VERSION ""

NS_ :

BS_:

BU_: XXX
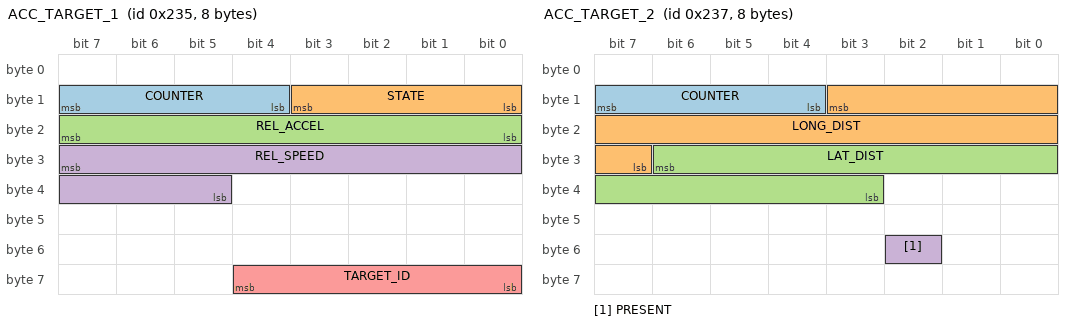
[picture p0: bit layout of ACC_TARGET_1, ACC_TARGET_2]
BO_ 565 ACC_TARGET_1: 8 XXX
 SG_ COUNTER : 15|4@0+ (1,0) [0|15] "" XXX
 SG_ STATE : 11|4@0+ (1,0) [0|15] "" XXX
 SG_ REL_ACCEL : 23|8@0+ (0.125,-12.5) [-12.5|19.375] "m/s^2" XXX
 SG_ REL_SPEED : 31|11@0+ (0.125,-128) [-128|127.875] "m/s" XXX
 SG_ TARGET_ID : 60|5@0+ (1,0) [0|31] "" XXX

BO_ 567 ACC_TARGET_2: 8 XXX
 SG_ COUNTER : 15|4@0+ (1,0) [0|15] "" XXX
 SG_ LONG_DIST : 11|13@0+ (0.025,0) [0|204.775] "m" XXX
 SG_ LAT_DIST : 30|12@0+ (0.01,-20) [-20|20.95] "m" XXX
 SG_ PRESENT : 50|1@0+ (1,0) [0|1] "" XXX

BO_ 569 ACC_TARGET_3: 8 XXX
 SG_ TIMESTAMP : 26|32@0+ (1,0) [0|4294967295] "us" XXX

CM_ "Continental ARS510 front radar (Toyota RAV4 2022-25, fwdRadar 8821F0R03100), radar bus: the target the radar's own ACC follows. The 0x80 object list and 0x85 metadata record span many frames and are decoded by ars510-radar (ars510/).";
CM_ BO_ 565 "ACC target, part 1: 50 Hz, content updated once per 60 ms radar cycle.";
CM_ SG_ 565 STATE "5 = target present, 1 = idle (all other fields zero).";
CM_ SG_ 565 REL_ACCEL "Target acceleration relative to ego.";
CM_ SG_ 565 REL_SPEED "Closing speed relative to ego, negative = closing.";
CM_ SG_ 565 TARGET_ID "Changes when the radar switches to a different target.";
CM_ BO_ 567 "ACC target, part 2: 50 Hz.";
CM_ SG_ 567 LONG_DIST "Distance from the radar.";
CM_ SG_ 567 LAT_DIST "Lateral position, left positive.";
CM_ SG_ 567 PRESENT "1 = target present.";
CM_ BO_ 569 "ACC target, part 3: 50 Hz.";
CM_ SG_ 569 TIMESTAMP "Radar cycle clock: changes once per 60 ms radar cycle, when the ACC target is recomputed.";
VAL_ 565 STATE 5 "TARGET" 1 "NO_TARGET" ;
